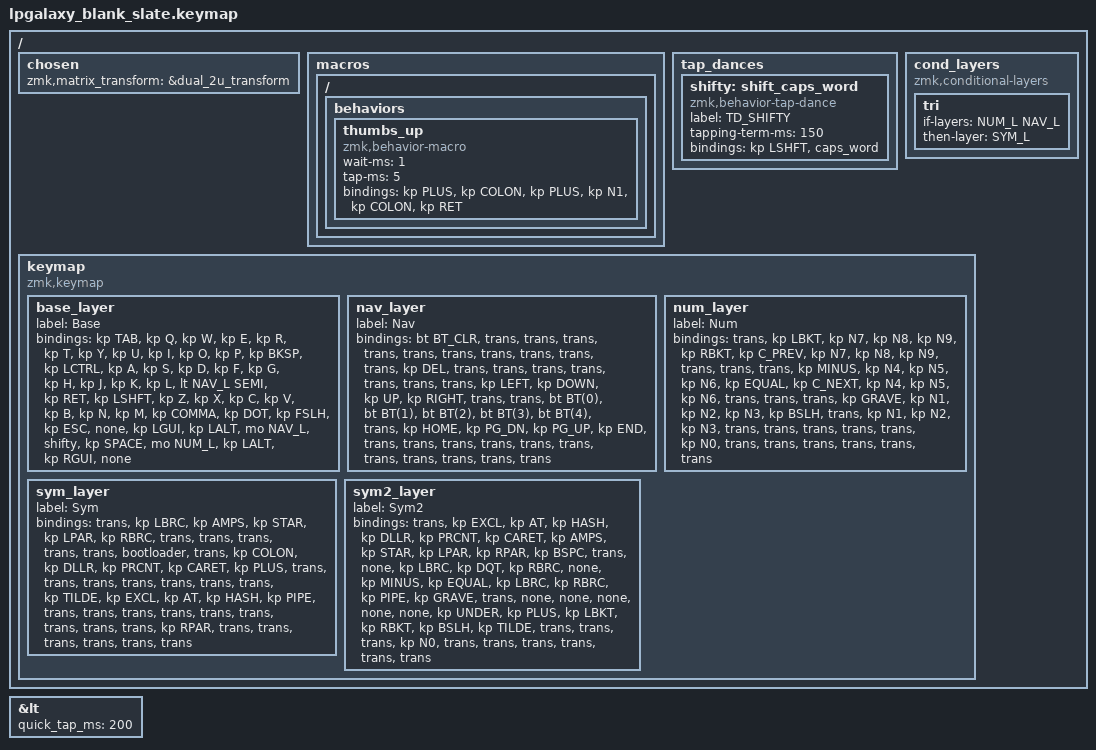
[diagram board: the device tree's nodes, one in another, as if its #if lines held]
/*
 * Copyright (c) 2022 Pete Johanson
 *
 * SPDX-License-Identifier: MIT
 */

#include <behaviors.dtsi>
#include <dt-bindings/zmk/keys.h>
#include <dt-bindings/zmk/bt.h>
#include <dt-bindings/zmk/outputs.h>

#define QWERTY_BASE 1

#define TBLE_ORTHO   1
// #define TBLE_MIT     1
// #define TBLE_DUAL_2U 1

#define NAV_L 1
#define NUM_L 2
#define SYM_L 3
#define SYM2_L 4

// Using layer taps on thumbs, having quick tap as well helps w/ repeating space/backspace
&lt { quick_tap_ms = <200>; };

#define BT(n) BT_SEL n

/ {
    chosen {
        zmk,matrix_transform =
        #ifdef TBLE_DUAL_2U
            &dual_2u_transform;
        #elif defined(TBLE_MIT)
            &mit_transform;
        #else
            &ortho_transform;
        #endif
    };

    macros {
      ZMK_MACRO(thumbs_up,
		wait-ms = <1>;
		tap-ms = <5>;
                bindings = <&kp PLUS &kp COLON &kp PLUS &kp N1 &kp COLON &kp RET>;
		)
    };
    
    tap_dances {
    	shifty: shift_caps_word {
            compatible = "zmk,behavior-tap-dance";
            label = "TD_SHIFTY";
            #binding-cells = <0>;
            tapping-term-ms = <150>;
            bindings = <&kp LSHFT>, <&caps_word>;
        };
    };

// Conditional layer only when we have less thumb keys
// #ifdef TBLE_DUAL_2U
    cond_layers {
        compatible = "zmk,conditional-layers";
	tri {
	    if-layers = <NUM_L NAV_L>;
	    then-layer = <SYM_L>;
        };
    };
// #endif

    keymap {
        compatible = "zmk,keymap";

        base_layer {
            label = "Base";
            bindings = <
#ifdef QWERTY_BASE
 &kp TAB    &kp Q      &kp W      &kp E       &kp R          &kp T          &kp Y            &kp U          &kp I       &kp O      &kp P           &kp BKSP
 &kp LCTRL  &kp A      &kp S      &kp D       &kp F          &kp G          &kp H            &kp J          &kp K       &kp L      &lt NAV_L SEMI  &kp RET
 &kp LSHFT  &kp Z      &kp X      &kp C       &kp V          &kp B          &kp N            &kp M          &kp COMMA   &kp DOT    &kp FSLH        &kp ESC
#else
 &kp TAB    &kp Q      &kp W      &kp F       &kp P          &kp B          &kp J            &kp L          &kp U       &kp Y      &kp QUOT      &kp BKSP
 &kp LCTRL  &kp A      &kp S      &kp D       &kp F          &kp G          &kp H            &kp J          &kp K       &kp L      &lt NAV_L SEMI  &kp RET
 &kp LSHFT  &kp Z      &kp X      &kp C       &kp D          &kp V          &kp K            &kp H          &kp COMMA   &kp DOT    &kp SEMI      &kp ESC
#endif
#ifdef TBLE_DUAL_2U
 &none  &kp LGUI   &kp LALT  &mo NAV_L         &shifty                        &kp SPACE              &mo NUM_L   &kp LALT   &kp RGUI      &none
#elif defined(TBLE_MIT)
 &none  &kp LCTRL  &kp LALT  &kp LGUI  &mo NUM_L    &mt LSHFT SPACE               &mo NAV_L      &kp LEFT    &kp UP     &kp DOWN      &none
#else
 &none  &kp LCTRL  &kp LALT  &kp LGUI  &mo NUM_L    &mt LSHFT SPACE    &mt LSHFT SPACE   &mo SYM2_L      &kp LEFT    &kp UP     &kp DOWN      &none
#endif
            >;
        };

        nav_layer {
            label = "Nav";
            bindings = <
&bt BT_CLR &trans     &trans     &trans      &trans          &trans       &trans     &trans         &trans      &trans     &trans     &kp DEL
&trans     &trans     &trans     &trans      &trans          &trans       &trans     &kp LEFT       &kp DOWN    &kp UP     &kp RIGHT  &trans
&trans     &bt BT(0)  &bt BT(1)  &bt BT(2)   &bt BT(3)       &bt BT(4)    &trans     &kp HOME       &kp PG_DN   &kp PG_UP  &kp END    &trans
#ifdef TBLE_DUAL_2U
&trans  &trans        &trans     &trans              &trans                    &trans       &trans         &trans &trans &trans
#elif defined(TBLE_MIT)
&trans  &trans        &trans     &trans      &trans                &trans             &trans      &trans   &trans &trans &trans
#else
&trans  &trans        &trans     &trans      &trans          &trans       &trans    &trans  &trans         &trans &trans &trans
#endif
            >;
        };

        num_layer {
            label = "Num";
            bindings = <
&trans     &kp LBKT   &kp N7 &kp N8 &kp N9    &kp RBKT    &kp C_PREV    &kp N7     &kp N8      &kp N9       &trans     &trans
&trans     &kp MINUS  &kp N4 &kp N5 &kp N6    &kp EQUAL   &kp C_NEXT    &kp N4     &kp N5      &kp N6       &trans     &trans
&trans     &kp GRAVE  &kp N1 &kp N2 &kp N3    &kp BSLH    &trans        &kp N1     &kp N2      &kp N3       &trans     &trans
#ifdef TBLE_DUAL_2U
&trans  &trans       &trans     &kp N0              &trans                 &trans            &trans         &trans &trans &trans
#elif defined(TBLE_MIT)
&trans  &trans       &trans     &kp N0      &trans           &none            &trans        &none      &trans &trans &trans
#else
&trans  &trans       &trans     &kp N0      &trans    &none         &none     &none        &none      &trans &trans &trans
#endif
            >;
        };

        sym_layer {
            label = "Sym";
            bindings = <
&trans     &kp LBRC   &kp AMPS   &kp STAR    &kp LPAR     &kp RBRC     &trans     &trans    &trans       &trans       &trans     &bootloader
&trans     &kp COLON  &kp DLLR   &kp PRCNT   &kp CARET    &kp PLUS     &trans     &trans    &trans       &trans       &trans     &trans
&trans     &kp TILDE  &kp EXCL   &kp AT      &kp HASH     &kp PIPE     &trans     &trans    &trans       &trans       &trans     &trans
#ifdef TBLE_DUAL_2U
&trans &trans        &trans     &kp RPAR                &trans                    &trans       &trans         &trans &trans &trans
#elif defined(TBLE_MIT)
&trans &trans        &trans     &kp RPAR        &trans                &trans             &trans      &trans   &trans &trans &trans
#else
&trans &trans        &trans     &kp RPAR        &trans          &trans       &trans    &trans  &trans         &trans &trans &trans
#endif
            >;
        };

        sym2_layer {
            label = "Sym2";
            bindings = <
&trans   &kp EXCL  &kp AT    &kp HASH  &kp DLLR  &kp PRCNT  &kp CARET  &kp AMPS   &kp STAR  &kp LPAR &kp RPAR &kp BSPC
&trans   &none     &kp LBRC  &kp DQT   &kp RBRC  &none      &kp MINUS  &kp EQUAL  &kp LBRC  &kp RBRC &kp PIPE &kp GRAVE
&trans   &none     &none     &none     &none     &none      &kp UNDER  &kp PLUS   &kp LBKT  &kp RBKT &kp BSLH &kp TILDE
#ifdef TBLE_DUAL_2U
&trans  &trans       &trans     &kp N0              &trans                 &trans            &trans         &trans &trans &trans
#elif defined(TBLE_MIT)
&trans  &trans       &trans     &kp N0      &trans           &none            &trans        &none      &trans &trans &trans
#else
&trans  &trans       &trans     &kp N0      &trans    &none         &none     &none        &none      &trans &trans &trans
#endif
            >;
        };

    };
};

